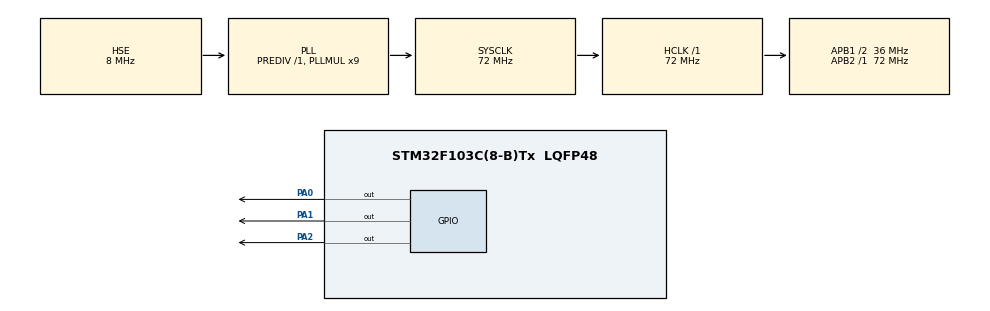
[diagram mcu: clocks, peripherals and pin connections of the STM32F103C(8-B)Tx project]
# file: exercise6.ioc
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FREERTOS.Tasks01=defaultTask,0,128,StartDefaultTask,Default,NULL,Dynamic,NULL,NULL;Task01,-2,128,greenLedTask,Default,NULL,Dynamic,NULL,NULL;Task02,2,128,redLedTask,Default,NULL,Dynamic,NULL,NULL
Mcu.Family=STM32F1
Mcu.Name=STM32F103C(8-B)Tx
Mcu.Package=LQFP48
NVIC.PriorityGroup=NVIC_PRIORITYGROUP_4
PA0-WKUP.Signal=GPIO_Output
PA1.Signal=GPIO_Output
PA13.Mode=Serial_Wire
PA13.Signal=SYS_JTMS-SWDIO
PA14.Mode=Serial_Wire
PA14.Signal=SYS_JTCK-SWCLK
PA2.Signal=GPIO_Output
PD0-OSC_IN.Mode=HSE-External-Oscillator
PD0-OSC_IN.Signal=RCC_OSC_IN
PD1-OSC_OUT.Mode=HSE-External-Oscillator
PD1-OSC_OUT.Signal=RCC_OSC_OUT
ProjectManager.HeapSize=0x200
ProjectManager.StackSize=0x400
ProjectManager.TargetToolchain=STM32CubeIDE
RCC.AHBFreq_Value=72000000
RCC.APB1CLKDivider=RCC_HCLK_DIV2
RCC.APB1Freq_Value=36000000
RCC.APB1TimFreq_Value=72000000
RCC.APB2Freq_Value=72000000
RCC.APB2TimFreq_Value=72000000
RCC.HCLKFreq_Value=72000000
RCC.PLLMUL=RCC_PLL_MUL9
RCC.PLLSourceVirtual=RCC_PLLSOURCE_HSE
RCC.SYSCLKFreq_VALUE=72000000
RCC.SYSCLKSource=RCC_SYSCLKSOURCE_PLLCLK
RCC.USBFreq_Value=72000000
VP_FREERTOS_VS_CMSIS_V1.Mode=CMSIS_V1
board=custom

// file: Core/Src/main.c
/* USER CODE BEGIN Header */
/**
  ******************************************************************************
  * @file           : main.c
  * @brief          : Main program body
  ******************************************************************************
  * @attention
  *
  * Copyright (c) 2024 STMicroelectronics.
  * All rights reserved.
  *
  * This software is licensed under terms that can be found in the LICENSE file
  * in the root directory of this software component.
  * If no LICENSE file comes with this software, it is provided AS-IS.
  *
  ******************************************************************************
  */
/* USER CODE END Header */

#include "main.h"
#include "cmsis_os.h"

/* USER CODE BEGIN PD */
static volatile uint8_t StartFlag = 1;
/* USER CODE END PD */

osThreadId defaultTaskHandle;
osThreadId Task01Handle;
osThreadId Task02Handle;
volatile int collisionCount = 0;

void SystemClock_Config(void);
static void MX_GPIO_Init(void);
void greenLedTask(void const * argument);
void redLedTask(void const * argument);

int main(void) {

/* Reset of all peripherals, Initializes the Flash interface and the Systick. */

	HAL_Init();

	  /* Configure the system clock */
    SystemClock_Config();

    /* Initialize all configured peripherals */
    MX_GPIO_Init();

    /* Create the thread(s) */
    /* definition and creation of defaultTask */

    /* Create tasks */
    osThreadDef(Task01, greenLedTask, osPriorityLow, 0, 128);
    Task01Handle = osThreadCreate(osThread(Task01), NULL);

    osThreadDef(Task02, redLedTask, osPriorityHigh, 0, 128);
    Task02Handle = osThreadCreate(osThread(Task02), NULL);

    /* Start scheduler */
    osKernelStart();

    while (1) {
        // Infinite loop - should never reach here
    }
}

/* Shared Resource Access Function */
void AccessSharedData() {
    if (StartFlag == 1) {
    	HAL_GPIO_WritePin(GPIOA, GPIO_PIN_2, GPIO_PIN_SET); // Turn Blue LED OFF
        StartFlag = 0;
        osDelay(500); // Simulate read/write operation for 1 second
        StartFlag = 1;// Set flag down
    } else if (StartFlag == 0){
        HAL_GPIO_WritePin(GPIOA, GPIO_PIN_2, GPIO_PIN_RESET); // Turn Blue LED ON
    }

}

/* Green LED Task */
void greenLedTask(void const * argument) {
    while (1) {
        HAL_GPIO_WritePin(GPIOA, GPIO_PIN_0, GPIO_PIN_RESET); // Green LED ON
        taskENTER_CRITICAL();
        AccessSharedData(); // Access shared resource
        taskEXIT_CRITICAL();
        HAL_GPIO_WritePin(GPIOA, GPIO_PIN_0, GPIO_PIN_SET);   // Green LED OFF
        osDelay(500); // Wait for 500ms
    }
}

/* Red LED Task */
void redLedTask(void const * argument) {
    while (1) {
        HAL_GPIO_WritePin(GPIOA, GPIO_PIN_1, GPIO_PIN_RESET); // Red LED ON
        taskENTER_CRITICAL();
        AccessSharedData(); // Access shared resource
        taskEXIT_CRITICAL();
        HAL_GPIO_WritePin(GPIOA, GPIO_PIN_1, GPIO_PIN_SET);   // Red LED OFF
        osDelay(100); // Wait for 100ms
    }
}

/* System Clock Configuration */
void SystemClock_Config(void) {
    RCC_OscInitTypeDef RCC_OscInitStruct = {0};
    RCC_ClkInitTypeDef RCC_ClkInitStruct = {0};

    /** Initializes the RCC Oscillators according to the specified parameters
    * in the RCC_OscInitTypeDef structure.
    */
    RCC_OscInitStruct.OscillatorType = RCC_OSCILLATORTYPE_HSE;
    RCC_OscInitStruct.HSEState = RCC_HSE_ON;
    RCC_OscInitStruct.HSEPredivValue = RCC_HSE_PREDIV_DIV1;
    RCC_OscInitStruct.HSIState = RCC_HSI_ON;
    RCC_OscInitStruct.PLL.PLLState = RCC_PLL_ON;
    RCC_OscInitStruct.PLL.PLLSource = RCC_PLLSOURCE_HSE; // Corrected field name
    RCC_OscInitStruct.PLL.PLLMUL = RCC_PLL_MUL9;
    if (HAL_RCC_OscConfig(&RCC_OscInitStruct) != HAL_OK) {
        Error_Handler();
    }

    /** Initializes the CPU, AHB and APB buses clocks
    */
    RCC_ClkInitStruct.ClockType = RCC_CLOCKTYPE_HCLK | RCC_CLOCKTYPE_SYSCLK |
                                  RCC_CLOCKTYPE_PCLK1 | RCC_CLOCKTYPE_PCLK2;
    RCC_ClkInitStruct.SYSCLKSource = RCC_SYSCLKSOURCE_PLLCLK;
    RCC_ClkInitStruct.AHBCLKDivider = RCC_SYSCLK_DIV1;
    RCC_ClkInitStruct.APB1CLKDivider = RCC_HCLK_DIV2;
    RCC_ClkInitStruct.APB2CLKDivider = RCC_HCLK_DIV1;

    if (HAL_RCC_ClockConfig(&RCC_ClkInitStruct, FLASH_LATENCY_2) != HAL_OK) {
        Error_Handler();
    }
}

/* GPIO Initialization */
static void MX_GPIO_Init(void) {
    GPIO_InitTypeDef GPIO_InitStruct = {0};

    /* Enable GPIO Clocks */
    __HAL_RCC_GPIOA_CLK_ENABLE();

    /* Configure GPIO pins */
    GPIO_InitStruct.Pin = GPIO_PIN_0 | GPIO_PIN_1 | GPIO_PIN_2;
    GPIO_InitStruct.Mode = GPIO_MODE_OUTPUT_PP;
    GPIO_InitStruct.Pull = GPIO_NOPULL;
    GPIO_InitStruct.Speed = GPIO_SPEED_FREQ_LOW;
    HAL_GPIO_Init(GPIOA, &GPIO_InitStruct);

    /* Set GPIO initial state */
    HAL_GPIO_WritePin(GPIOA, GPIO_PIN_0 | GPIO_PIN_1 | GPIO_PIN_2, GPIO_PIN_SET);
}

/* Error Handler */
void Error_Handler(void) {
    __disable_irq();
    while (1) {
        // Infinite loop in case of error
    }
}
